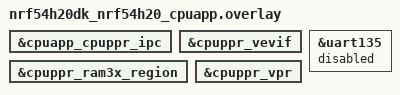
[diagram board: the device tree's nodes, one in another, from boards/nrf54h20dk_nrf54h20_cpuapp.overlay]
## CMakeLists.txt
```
cmake_minimum_required(VERSION 3.20.0)
find_package(Zephyr REQUIRED HINTS $ENV{ZEPHYR_BASE})

project(hello_world_ipc)

target_sources(app PRIVATE src/main.c)
```

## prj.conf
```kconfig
CONFIG_PRINTK=y

CONFIG_IPC_SERVICE=y
CONFIG_IPC_SERVICE_BACKEND_ICBMSG=y
CONFIG_MBOX=y
```

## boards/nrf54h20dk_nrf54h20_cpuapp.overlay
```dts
ipc1: &cpuapp_cpuppr_ipc {
	status = "okay";
};

&cpuppr_vevif {
	status = "okay";
};

&cpuppr_ram3x_region {
	status = "okay";
};

&uart135 {
	status = "disabled";
};

&cpuppr_vpr {
	status = "okay";
};
```

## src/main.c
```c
#include <zephyr/kernel.h>
#include <zephyr/ipc/ipc_service.h>

K_SEM_DEFINE(bound_sem, 0, 1);

static void bound_cb(void *priv)
{
	k_sem_give(&bound_sem);
}

static void recv_cb(const void *data, size_t len, void *priv)
{
	unsigned char *message;

	message = (unsigned char *)data;
	printk("%s", message);
}

static struct ipc_ept_cfg ept0_cfg = {
	.name = "ept0",
	.cb = {
		.bound	 = bound_cb,
		.received = recv_cb,
	},
};

int main(void)
{
	const struct device *inst0;
	struct ipc_ept ept_rad;
	int ret;

	inst0 = DEVICE_DT_GET(DT_NODELABEL(ipc1));
	ret = ipc_service_open_instance(inst0);
	ret = ipc_service_register_endpoint(inst0, &ept_rad, &ept0_cfg);

	k_sem_take(&bound_sem, K_FOREVER);

	printk("Hello world from nRF54H20 cpuapp\n");
	
	while(1) {
		printk("%s is active for %u seconds\n", CONFIG_BOARD_TARGET, k_uptime_seconds());
		k_msleep(1000);
	}

	return 0;
}
```
